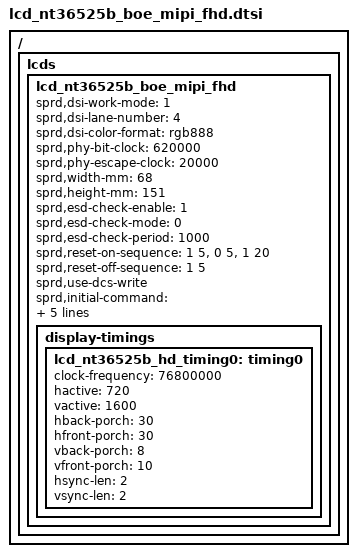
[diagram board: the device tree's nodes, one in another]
/*
 * GD9365 HTT LCD config dtsi file for spreadtrum
 *
 * Copyright (C) 2020, Spreadtrum Communications Inc.
 *
 * SPDX-License-Identifier: (GPL-2.0+ OR MIT)
 */

/ { lcds {
	lcd_nt36525b_boe_mipi_fhd: lcd_nt36525b_boe_mipi_fhd {

		sprd,dsi-work-mode = <1>; /* video burst mode*/
		sprd,dsi-lane-number = <4>;
		sprd,dsi-color-format = "rgb888";

		sprd,phy-bit-clock = <620000>;	/* kbps */
		sprd,phy-escape-clock = <20000>;/* kHz */

		sprd,width-mm = <68>;
		sprd,height-mm = <151>;

		sprd,esd-check-enable = <1>;
		sprd,esd-check-mode = <0>;
		sprd,esd-check-period = <1000>;

		sprd,reset-on-sequence = <1 5>, <0 5>, <1 20>;
		sprd,reset-off-sequence = <1 5>;

		sprd,use-dcs-write;

		sprd,initial-command = [
			15 00 00 02 FF 20

			15 00 00 02 FB 01
			15 00 00 02 01 55
			15 00 00 02 03 55
			15 00 00 02 05 99
			15 00 00 02 07 4B
			15 00 00 02 08 DF
			15 00 00 02 0E 69
			15 00 00 02 0F 7D
			15 00 00 02 89 BD
			15 00 00 02 8A BD
			15 00 00 02 8B BD
			15 00 00 02 8C BD
			15 00 00 02 8D BD
			15 00 00 02 8E BD

			15 00 00 02 94 C0
			15 00 00 02 95 13
			15 00 00 02 96 13

			15 00 00 02 69 91
			15 00 00 02 1F 02



			15 00 00 02 FF 20

			15 00 00 02 FB 01

			39 00 00 11 B0 00 00 00 01 00 2E 00 46 00 5A 00 6D 00 7E 00 8F
			39 00 00 11 B1 00 9D 00 D3 00 FC 01 40 01 71 01 C5 02 03 02 06
			39 00 00 11 B2 02 44 02 87 02 B6 02 EB 03 13 03 3E 03 50 03 5F
			39 00 00 0d B3 03 73 03 8B 03 A9 03 C7 03 D9 03 DC

			39 00 00 11 B4 00 00 00 01 00 2E 00 46 00 5A 00 6D 00 7E 00 8F
			39 00 00 11 B5 00 9D 00 D3 00 FC 01 40 01 71 01 C5 02 03 02 06
			39 00 00 11 B6 02 44 02 87 02 B6 02 EB 03 13 03 3E 03 50 03 5F
			39 00 00 0d B7 03 73 03 8B 03 A9 03 C7 03 D9 03 DC

			39 00 00 11 B8 00 00 00 01 00 2E 00 46 00 5A 00 6D 00 7E 00 8F
			39 00 00 11 B9 00 9D 00 D3 00 FC 01 40 01 71 01 C5 02 03 02 06
			39 00 00 11 BA 02 44 02 87 02 B6 02 EB 03 13 03 3E 03 50 03 5F
			39 00 00 0d BB 03 73 03 8B 03 A9 03 C7 03 D9 03 DC

			15 00 00 02 FF 21

			15 00 00 02 FB 01

			39 00 00 11 B0 00 00 00 01 00 26 00 3E 00 52 00 65 00 76 00 87
			39 00 00 11 B1 00 95 00 CB 00 F4 01 38 01 69 01 BD 01 FB 01 FE
			39 00 00 11 B2 02 3C 02 7F 02 AE 02 E3 03 0B 03 36 03 48 03 57
			39 00 00 0d B3 03 6B 03 83 03 A1 03 BF 03 D9 03 DC

			39 00 00 11 B4 00 00 00 01 00 26 00 3E 00 52 00 65 00 76 00 87
			39 00 00 11 B5 00 95 00 CB 00 F4 01 38 01 69 01 BD 01 FB 01 FE
			39 00 00 11 B6 02 3C 02 7F 02 AE 02 E3 03 0B 03 36 03 48 03 57
			39 00 00 0d B7 03 6B 03 83 03 A1 03 BF 03 D9 03 DC

			39 00 00 11 B8 00 00 00 01 00 26 00 3E 00 52 00 65 00 76 00 87
			39 00 00 11 B9 00 95 00 CB 00 F4 01 38 01 69 01 BD 01 FB 01 FE
			39 00 00 11 BA 02 3C 02 7F 02 AE 02 E3 03 0B 03 36 03 48 03 57
			39 00 00 0d BB 03 6B 03 83 03 A1 03 BF 03 D9 03 DC

			15 00 00 02 FF 23

			15 00 00 02 FB 01
			15 00 00 02 12 B4
			15 00 00 02 15 E9
			15 00 00 02 16 0B


			15 00 00 02 FF 24

			15 00 00 02 FB 01
			15 00 00 02 93 0A
			15 00 00 02 94 0A
			15 00 00 02 00 00
			15 00 00 02 01 1E
			15 00 00 02 02 1D
			15 00 00 02 03 21
			15 00 00 02 04 04
			15 00 00 02 05 05
			15 00 00 02 06 1F
			15 00 00 02 07 20
			15 00 00 02 08 0C
			15 00 00 02 09 0D
			15 00 00 02 0A 0E
			15 00 00 02 0B 0F
			15 00 00 02 0C 00
			15 00 00 02 0D 00
			15 00 00 02 0E 00
			15 00 00 02 0F 00
			15 00 00 02 10 00
			15 00 00 02 11 00
			15 00 00 02 12 00
			15 00 00 02 13 00
			15 00 00 02 14 00
			15 00 00 02 15 00
			15 00 00 02 16 00
			15 00 00 02 17 1E
			15 00 00 02 18 1D
			15 00 00 02 19 21
			15 00 00 02 1A 04
			15 00 00 02 1B 05
			15 00 00 02 1C 1F
			15 00 00 02 1D 20
			15 00 00 02 1E 0C
			15 00 00 02 1F 0D
			15 00 00 02 20 0E
			15 00 00 02 21 0F
			15 00 00 02 22 00
			15 00 00 02 23 00
			15 00 00 02 24 00
			15 00 00 02 25 00
			15 00 00 02 26 00
			15 00 00 02 27 00
			15 00 00 02 28 00
			15 00 00 02 29 00
			15 00 00 02 2A 00
			15 00 00 02 2B 00
			15 00 00 02 2F 08
			15 00 00 02 30 06
			15 00 00 02 31 00
			15 00 00 02 32 00
			15 00 00 02 33 06
			15 00 00 02 34 08
			15 00 00 02 35 00
			15 00 00 02 36 00
			15 00 00 02 37 44
			15 00 00 02 38 44
			15 00 00 02 39 00
			15 00 00 02 3A 24
			15 00 00 02 3B 88
			15 00 00 02 3D 52
			15 00 00 02 4D 34
			15 00 00 02 4E 12
			15 00 00 02 4F 00
			15 00 00 02 50 00
			15 00 00 02 51 21
			15 00 00 02 52 43
			15 00 00 02 53 00
			15 00 00 02 54 00
			15 00 00 02 55 47
			15 00 00 02 56 44
			15 00 00 02 58 21
			15 00 00 02 59 00
			15 00 00 02 5A 24
			15 00 00 02 5B 88
			15 00 00 02 5C 80
			15 00 00 02 5D 0F
			15 00 00 02 5E 04
			15 00 00 02 5F 00
			15 00 00 02 88 2E
			15 00 00 02 89 40
			15 00 00 02 8A 8F
			15 00 00 02 8D 00
			15 00 00 02 8E 0F
			15 00 00 02 60 80
			15 00 00 02 61 90
			15 00 00 02 64 10
			15 00 00 02 80 08
			15 00 00 02 81 04
			15 00 00 02 82 08
			15 00 00 02 83 04

			15 00 00 02 84 00

			15 00 00 02 85 01
			15 00 00 02 86 04
			15 00 00 02 91 40
			15 00 00 02 92 A7
			15 00 00 02 98 80
			15 00 00 02 AB 00
			15 00 00 02 AD 00
			15 00 00 02 AF 04
			15 00 00 02 B0 05
			15 00 00 02 B1 A3


			15 00 00 02 FF 25

			15 00 00 02 FB 01
			15 00 00 02 17 82
			15 00 00 02 18 06
			15 00 00 02 19 0F
			15 00 00 02 1E 00
			15 00 00 02 1F 24
			15 00 00 02 20 88
			15 00 00 02 23 05
			15 00 00 02 24 A3
			15 00 00 02 25 00
			15 00 00 02 26 24
			15 00 00 02 27 88
			15 00 00 02 2A 05
			15 00 00 02 2B A3
			15 00 00 02 2F 55
			15 00 00 02 30 11
			15 00 00 02 31 00
			15 00 00 02 32 00
			15 00 00 02 33 24
			15 00 00 02 34 88
			15 00 00 02 37 05
			15 00 00 02 38 A3
			15 00 00 02 40 11
			15 00 00 02 41 80
			15 00 00 02 42 24
			15 00 00 02 43 88
			15 00 00 02 46 05
			15 00 00 02 47 A3
			15 00 00 02 49 00
			15 00 00 02 4A 00
			15 00 00 02 4B 24
			15 00 00 02 4C 88
			15 00 00 02 4F 24
			15 00 00 02 50 88
			15 00 00 02 53 05
			15 00 00 02 54 A3
			15 00 00 02 55 05
			15 00 00 02 56 A3
			15 00 00 02 5A 22
			15 00 00 02 5B C0
			15 00 00 02 5C 00
			15 00 00 02 5D 24
			15 00 00 02 5E 88
			15 00 00 02 61 24
			15 00 00 02 62 88
			15 00 00 02 65 05
			15 00 00 02 66 A3
			15 00 00 02 8A 00
			15 00 00 02 C0 07
			15 00 00 02 C2 84
			15 00 00 02 C6 92
			15 00 00 02 CA 1C
			15 00 00 02 CC 1C
			15 00 00 02 CD 00
			15 00 00 02 CE 00
			15 00 00 02 D3 11
			15 00 00 02 D4 CC
			15 00 00 02 D5 11
			15 00 00 02 D6 1C
			15 00 00 02 D7 11
			15 00 00 02 0A 82
			15 00 00 02 0B 79
			15 00 00 02 0C 01


			15 00 00 02 FF 26

			15 00 00 02 FB 01
			15 00 00 02 00 A1
			15 00 00 02 04 4A
			15 00 00 02 06 FF
			15 00 00 02 0C 0B
			15 00 00 02 0D 01
			15 00 00 02 0E 02
			15 00 00 02 0F 06
			15 00 00 02 10 07
			15 00 00 02 11 00
			15 00 00 02 13 28
			15 00 00 02 14 90
			15 00 00 02 16 81
			15 00 00 02 19 1A
			15 00 00 02 1A 0D
			15 00 00 02 1B 12
			15 00 00 02 1C 82
			15 00 00 02 1D 00
			15 00 00 02 1E A7
			15 00 00 02 1F A7
			15 00 00 02 24 00
			15 00 00 02 25 A7
			15 00 00 02 26 66
			15 00 00 02 27 66
			15 00 00 02 28 66
			15 00 00 02 29 06
			15 00 00 02 2F 02
			15 00 00 02 30 A7
			15 00 00 02 31 11
			15 00 00 02 32 11
			15 00 00 02 34 03
			15 00 00 02 35 A7
			15 00 00 02 36 78
			15 00 00 02 37 66
			15 00 00 02 38 66
			15 00 00 02 39 06
			15 00 00 02 3F 04
			15 00 00 02 40 A7
			15 00 00 02 41 00
			15 00 00 02 42 00
			15 00 00 02 43 00


			15 00 00 02 FF 26

			15 00 00 02 FB 01
			15 00 00 02 58 CC
			15 00 00 02 59 CC
			15 00 00 02 5A CC
			15 00 00 02 5B CC
			15 00 00 02 5C 00
			15 00 00 02 5D 00
			15 00 00 02 5E 04
			15 00 00 02 5F 00
			15 00 00 02 60 00
			15 00 00 02 61 00
			15 00 00 02 63 24
			15 00 00 02 64 88
			15 00 00 02 67 24
			15 00 00 02 68 88
			15 00 00 02 6B 00
			15 00 00 02 6C 05
			15 00 00 02 6D 00
			15 00 00 02 70 05
			15 00 00 02 71 C8
			15 00 00 02 73 24
			15 00 00 02 74 88
			15 00 00 02 77 05
			15 00 00 02 78 C8
			15 00 00 02 79 00
			15 00 00 02 7A 24
			15 00 00 02 7B 88
			15 00 00 02 7E 05
			15 00 00 02 7F C8
			15 00 00 02 80 00
			15 00 00 02 81 00
			15 00 00 02 82 24
			15 00 00 02 83 88
			15 00 00 02 86 24
			15 00 00 02 87 88
			15 00 00 02 8A 05
			15 00 00 02 8B C8
			15 00 00 02 8C 00
			15 00 00 02 8D 00
			15 00 00 02 8E 01
			15 00 00 02 8F 00
			15 00 00 02 90 00
			15 00 00 02 91 00
			15 00 00 02 92 06
			15 00 00 02 93 40
			15 00 00 02 94 00
			15 00 00 02 95 00
			15 00 00 02 96 00
			15 00 00 02 99 0D
			15 00 00 02 9A 36
			15 00 00 02 9B 0C
			15 00 00 02 9C 9E
			15 00 00 02 44 33
			15 00 00 02 45 0E
			15 00 00 02 A9 46
			15 00 00 02 AA 40
			15 00 00 02 AB 52
			15 00 00 02 AC 4E
			15 00 00 02 AD 6C
			15 00 00 02 AE 34
			15 00 00 02 AF 72
			15 00 00 02 B0 58
			15 00 00 02 B1 4C
			15 00 00 02 B2 48
			15 00 00 02 B3 54
			15 00 00 02 B4 74
			15 00 00 02 B5 42
			15 00 00 02 B6 78
			15 00 00 02 B7 2E
			15 00 00 02 B8 3A
			15 00 00 02 B9 66
			15 00 00 02 BA 5E


			15 00 00 02 FF 27

			15 00 00 02 FB 01
			15 00 00 02 13 00
			15 00 00 02 14 55
			15 00 00 02 1F 55

			15 00 00 02 FF 24

			15 00 00 02 FB 01
			15 00 00 02 8D 80
			15 00 00 02 3A 86
			15 00 00 02 5A 86
			15 00 00 02 5D 08
			15 00 00 02 88 32
			15 00 00 02 89 C0
			15 00 00 02 8E 08

			15 00 00 02 FF 25

			15 00 00 02 FB 01
			15 00 00 02 56 23

			15 00 00 02 1F 86
			15 00 00 02 26 86
			15 00 00 02 33 86
			15 00 00 02 42 86
			15 00 00 02 4B 86
			15 00 00 02 4F 86
			15 00 00 02 5D 86
			15 00 00 02 61 86

			15 00 00 02 FF 26

			15 00 00 02 FB 01
			15 00 00 02 63 86
			15 00 00 02 67 86
			15 00 00 02 73 86
			15 00 00 02 7A 86
			15 00 00 02 82 86
			15 00 00 02 86 86

			15 00 00 02 FF 10

			15 00 00 02 FB 01
			15 00 00 02 BA 03
			13 78 00 01 11
			13 64 00 01 29
			];

		sprd,sleep-in-command = [
			13 0A 00 01 28
			13 78 00 01 10
			15 00 00 02 4F 01
			];

		sprd,sleep-out-command = [
			13 78 00 01 11
			13 64 00 01 29
			];

		display-timings {
			lcd_nt36525b_hd_timing0: timing0 {
				clock-frequency = <76800000>;
				hactive = <720>;
				vactive = <1600>;
				hback-porch = <30>;
				hfront-porch = <30>;
				vback-porch = <8>;
				vfront-porch = <10>;
				hsync-len = <2>;
				vsync-len = <2>;
			};
		};
	};
};};
